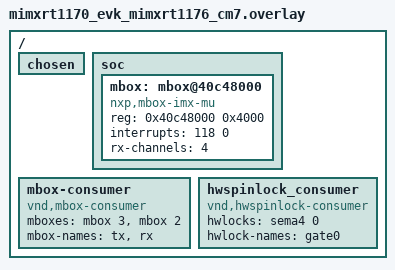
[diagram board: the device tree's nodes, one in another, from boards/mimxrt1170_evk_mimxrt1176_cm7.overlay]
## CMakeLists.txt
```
# Copyright 2025-2026 NXP
# SPDX-License-Identifier: Apache-2.0

cmake_minimum_required(VERSION 3.28.0)
find_package(Zephyr REQUIRED HINTS $ENV{ZEPHYR_BASE})

set(REMOTE_ZEPHYR_DIR ${CMAKE_CURRENT_BINARY_DIR}/../remote/zephyr)

if(CONFIG_BOARD_MIMXRT700_EVK_MIMXRT798S_CM33_CPU0 OR
   CONFIG_BOARD_FRDM_MCXN947_MCXN947_CPU0 OR
   CONFIG_BOARD_MCX_N9XX_EVK_MCXN947_CPU0 OR
   CONFIG_BOARD_MCX_N5XX_EVK_MCXN547_CPU0 OR
   CONFIG_BOARD_MIMXRT1180_EVK_MIMXRT1189_CM33 OR
   CONFIG_BOARD_FRDM_IMXRT1186_MIMXRT1186_CM33 OR
   CONFIG_BOARD_MIMXRT1170_EVK_MIMXRT1176_CM7 OR
   CONFIG_BOARD_MIMXRT1160_EVK_MIMXRT1166_CM7)
  message(STATUS "${BOARD}${BOARD_QUALIFIERS} compile as Main in this sample")
else()
  message(FATAL_ERROR "${BOARD}${BOARD_QUALIFIERS} is not supported for this sample")
endif()

project(hwspinlock)


if(CONFIG_INCLUDE_REMOTE_DIR)
  zephyr_include_directories(${REMOTE_ZEPHYR_DIR}/include/public)
endif()
target_sources(app PRIVATE src/main.c)
```

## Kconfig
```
# Copyright 2026 NXP
#
# SPDX-License-Identifier: Apache-2.0

source "Kconfig.zephyr"

config INCLUDE_REMOTE_DIR
	bool "Include remote core header directory"
	help
	  Include remote build header files. Can be used if primary image
	  needs to be aware of size or base address of secondary image
```

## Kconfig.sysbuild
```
# Copyright 2025-2026 NXP
# SPDX-License-Identifier: Apache-2.0

source "share/sysbuild/Kconfig"

config REMOTE_BOARD
	string "The board used for remote target"
	default "mcx_n9xx_evk/mcxn947/cpu1" if $(BOARD) = "mcx_n9xx_evk"
	default "mcx_n5xx_evk/mcxn547/cpu1" if $(BOARD) = "mcx_n5xx_evk"
	default "frdm_mcxn947/mcxn947/cpu1" if $(BOARD) = "frdm_mcxn947"
	default "mimxrt700_evk/mimxrt798s/cm33_cpu1" if $(BOARD) = "mimxrt700_evk"
	default "mimxrt1180_evk/mimxrt1189/cm7" if $(BOARD) = "mimxrt1180_evk"
	default "frdm_imxrt1186/mimxrt1186/cm7" if $(BOARD) = "frdm_imxrt1186"
	default "frdm_imxrt700/mimxrt798s/cm33_cpu1" if $(BOARD) = "frdm_imxrt700"
```

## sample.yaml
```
# Copyright 2025-2026 NXP
# SPDX-License-Identifier: Apache-2.0

sample:
  name: hwspinlock sample

common:
  sysbuild: true
  tags:
    - drivers
    - hwspinlock
    - mbox

tests:
  sample.drivers.hwspinlock:
    filter: dt_compat_enabled("nxp,sema42")
    platform_allow:
      - mcx_n9xx_evk/mcxn947/cpu0
      - frdm_mcxn947/mcxn947/cpu0
      - mimxrt700_evk/mimxrt798s/cm33_cpu0
      - mimxrt1180_evk/mimxrt1189/cm33
    integration_platforms:
      - mcx_n9xx_evk/mcxn947/cpu0
      - frdm_mcxn947/mcxn947/cpu0
      - mimxrt700_evk/mimxrt798s/cm33_cpu0
      - mimxrt1180_evk/mimxrt1189/cm33
```

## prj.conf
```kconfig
# Copyright 2025 NXP
# SPDX-License-Identifier: Apache-2.0

CONFIG_HWSPINLOCK=y
CONFIG_MBOX=y
CONFIG_PRINTK=y
```

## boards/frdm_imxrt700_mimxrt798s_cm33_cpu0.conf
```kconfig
# SPDX-FileCopyrightText: Copyright 2026 NXP
# SPDX-License-Identifier: Apache-2.0

CONFIG_SECOND_CORE_MCUX=y
CONFIG_INCLUDE_REMOTE_DIR=y
```

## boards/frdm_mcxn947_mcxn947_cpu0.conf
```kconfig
# Copyright 2025 NXP
# SPDX-License-Identifier: Apache-2.0

CONFIG_SECOND_CORE_MCUX=y
```

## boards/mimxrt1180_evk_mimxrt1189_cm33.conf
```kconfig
# Copyright 2026 NXP
# SPDX-License-Identifier: Apache-2.0

CONFIG_SECOND_CORE_MCUX=y
CONFIG_INCLUDE_REMOTE_DIR=y
```

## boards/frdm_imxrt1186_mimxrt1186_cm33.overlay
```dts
/*
 * Copyright 2026 NXP
 *
 * SPDX-License-Identifier: Apache-2.0
 */

/ {
	mbox-consumer {
		compatible = "vnd,mbox-consumer";
		mboxes = <&mbox1_a 1>, <&mbox1_a 0>;
		mbox-names = "tx", "rx";
	};

	hwspinlock_consumer {
		compatible = "vnd,hwspinlock-consumer";
		hwlocks = <&sema1 0>;
		hwlock-names = "gate0";
	};
};
```

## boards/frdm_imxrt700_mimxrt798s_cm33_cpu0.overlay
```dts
/*
 * SPDX-FileCopyrightText: Copyright 2026 NXP
 *
 * SPDX-License-Identifier: Apache-2.0
 */

/ {
	mbox-consumer {
		compatible = "vnd,mbox-consumer";
		mboxes = <&mbox1_a 1>, <&mbox1_a 0>;
		mbox-names = "tx", "rx";
	};

	hwspinlock_consumer {
		compatible = "vnd,hwspinlock-consumer";
		hwlocks = <&sema420 0>;
		hwlock-names = "gate0";
	};
};
```

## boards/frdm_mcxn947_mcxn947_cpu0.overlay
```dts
/*
 * Copyright 2025 NXP
 *
 * SPDX-License-Identifier: Apache-2.0
 */

/ {
	mbox_consumer {
		compatible = "vnd,mbox-consumer";
		mboxes = <&mbox 1>, <&mbox 0>;
		mbox-names = "tx", "rx";
	};

	hwspinlock_consumer {
		compatible = "vnd,hwspinlock-consumer";
		hwlocks = <&sema42 0>;
		hwlock-names = "gate0";
	};
};
```

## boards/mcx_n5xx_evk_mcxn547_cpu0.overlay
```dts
/*
 * Copyright 2026 NXP
 *
 * SPDX-License-Identifier: Apache-2.0
 */

/ {
	mbox_consumer {
		compatible = "vnd,mbox-consumer";
		mboxes = <&mbox 1>, <&mbox 0>;
		mbox-names = "tx", "rx";
	};

	hwspinlock_consumer {
		compatible = "vnd,hwspinlock-consumer";
		hwlocks = <&sema42 0>;
		hwlock-names = "gate0";
	};
};
```

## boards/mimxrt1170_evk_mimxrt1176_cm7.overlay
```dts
/*
 * Copyright 2026 NXP
 *
 * SPDX-License-Identifier: Apache-2.0
 */

/ {
	chosen {
		/* Delete ipc chosen property where old IPM mailbox driver below is
		 * configured.
		 */
		/delete-property/ zephyr,ipc;
	};

	soc {
		/* Delete IPM Driver node nxp,imx-mu */
		/delete-node/ mailbox@40c48000;

		/* Attach MBOX driver to MU Unit */
		mbox: mbox@40c48000 {
			compatible = "nxp,mbox-imx-mu";
			reg = <0x40c48000 0x4000>;
			interrupts = <118 0>;
			rx-channels = <4>;
			#mbox-cells = <1>;
			status = "okay";
		};
	};

	mbox-consumer {
		compatible = "vnd,mbox-consumer";
		mboxes = <&mbox 3>, <&mbox 2>;
		mbox-names = "tx", "rx";
	};

	hwspinlock_consumer {
		compatible = "vnd,hwspinlock-consumer";
		hwlocks = <&sema4 0>;
		hwlock-names = "gate0";
	};
};
```

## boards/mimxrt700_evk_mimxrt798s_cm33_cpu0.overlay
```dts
/*
 * Copyright 2026 NXP
 *
 * SPDX-License-Identifier: Apache-2.0
 */

/ {
	mbox-consumer {
		compatible = "vnd,mbox-consumer";
		mboxes = <&mbox1_a 1>, <&mbox1_a 0>;
		mbox-names = "tx", "rx";
	};

	hwspinlock_consumer {
		compatible = "vnd,hwspinlock-consumer";
		hwlocks = <&sema420 0>;
		hwlock-names = "gate0";
	};
};
```

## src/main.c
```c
/*
 * Copyright 2025 NXP
 *
 * SPDX-License-Identifier: Apache-2.0
 */

#include <zephyr/kernel.h>
#include <zephyr/drivers/mbox.h>
#include <zephyr/drivers/hwspinlock.h>
#include <zephyr/sys/printk.h>
#include <stdbool.h>

static K_SEM_DEFINE(rx_sem, 0, 1);

#define GATE_LOCK_TIMEOUT_MS 2000
#define GATE_LOCK_POLL_MS    1

static void callback(const struct device *dev, mbox_channel_id_t channel_id,
		     void *user_data, struct mbox_msg *data)
{
	ARG_UNUSED(dev);
	ARG_UNUSED(channel_id);
	ARG_UNUSED(user_data);
	ARG_UNUSED(data);

	/* ISR context: keep it minimal, just signal the main loop. */
	k_sem_give(&rx_sem);
}

int main(void)
{
	int ret;

	printk("Hello from HOST - %s\n", CONFIG_BOARD_TARGET);

	const struct mbox_dt_spec rx_channel = MBOX_DT_SPEC_GET(DT_PATH(mbox_consumer), rx);
	const struct mbox_dt_spec tx_channel = MBOX_DT_SPEC_GET(DT_PATH(mbox_consumer), tx);
	struct hwspinlock_dt_spec gate =
			HWSPINLOCK_DT_SPEC_GET_BY_NAME(DT_PATH(hwspinlock_consumer), gate0);

	if (!device_is_ready(rx_channel.dev)) {
		printk("HOST: MBOX device not ready\n");
		return 0;
	}
	if (!device_is_ready(tx_channel.dev)) {
		printk("HOST: MBOX device not ready\n");
		return 0;
	}
	if (!device_is_ready(gate.dev)) {
		printk("HOST: HWSPINLOCK device not ready\n");
		return 0;
	}

	printk("Maximum RX channels: %d\n", mbox_max_channels_get_dt(&rx_channel));
	printk("Maximum TX channels: %d\n", mbox_max_channels_get_dt(&tx_channel));
	printk("HWSPINLOCK max id: %u\n", hw_spinlock_get_max_id_dt(&gate));

	ret = mbox_register_callback_dt(&rx_channel, callback, NULL);
	if (ret < 0) {
		printk("HOST: Could not register callback (%d)\n", ret);
		return 0;
	}

	ret = mbox_set_enabled_dt(&rx_channel, true);
	if (ret < 0) {
		printk("HOST: Could not enable RX channel %d (%d)\n", rx_channel.channel_id, ret);
		return 0;
	}

	printk("Maximum bytes of data in the TX message: %d\n", mbox_mtu_get_dt(&tx_channel));
	printk("Demo: HOST locks gate, sends ping while holding it; REMOTE blocks on same gate then replies.\n");

	while (1) {
		k_busy_wait(1500000);

		/* Discard any stale/late pong from a previous iteration. */
		k_sem_reset(&rx_sem);

		k_spinlock_key_t key;
		bool have_lock = false;
		int64_t start_ms = k_uptime_get();

		while (true) {
			ret = hw_spin_trylock_dt(&gate, &key);
			if (ret == 0) {
				have_lock = true;
				break;
			}

			if (ret != -EBUSY) {
				printk("HOST: trylock returned unexpected error %d\n", ret);
				break;
			}

			if ((k_uptime_get() - start_ms) > GATE_LOCK_TIMEOUT_MS) {
				printk("HOST: timeout waiting for gate (%d ms)\n",
					GATE_LOCK_TIMEOUT_MS);
				break;
			}

			k_sleep(K_MSEC(GATE_LOCK_POLL_MS));
		}

		if (!have_lock) {
			continue;
		}

		printk("HOST: locked gate id=%u, sending ping on channel %d\n",
		       gate.id, tx_channel.channel_id);

		ret = mbox_send_dt(&tx_channel, NULL);
		if (ret < 0) {
			printk("HOST: could not send ping (%d)\n", ret);
			hw_spin_unlock_dt(&gate, key);
			continue;
		}

		/* Hold the lock a bit so REMOTE will observe contention. */
		k_busy_wait(600000);
		hw_spin_unlock_dt(&gate, key);
		printk("HOST: unlocked gate, waiting for pong...\n");

		/* Wait until RX callback gives rx_sem */
		ret = k_sem_take(&rx_sem, K_SECONDS(2));
		if (ret < 0) {
			printk("HOST: timeout waiting for pong (%d)\n", ret);
		} else {
			printk("HOST: received pong\n");
		}
	}

	return 0;
}
```
